# FRCTL_A_367.0 register map
Vendor: Texas Instruments
Peripheral module from a debugger description file (folder msp430).
Registers are 16-bit, read-write, no defined reset value unless marked. A register's access mark holds for its fields unless they carry their own. Offsets are as the file gives them; lines under a group give offsets from that group; [hi:lo] are bit positions; {n}, {i} and the like mark numbered series; 'fields as' and 'values as' point back to an identical list; <NAME> marks a mode.

## FRCTL_A
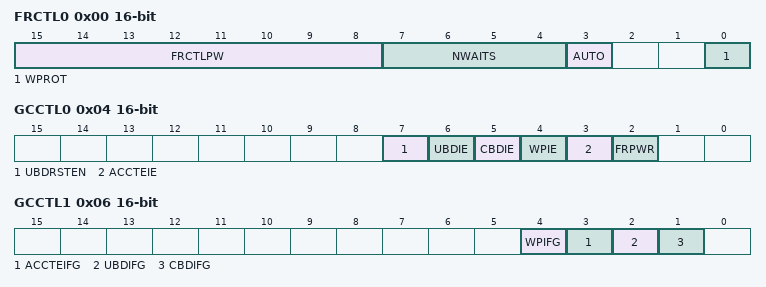
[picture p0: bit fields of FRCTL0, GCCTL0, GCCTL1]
0x00 FRCTL0 — FRAM Controller A Control Register 0
  [15:8] FRCTLPW — FRCTLPW password
  [7:4] NWAITS — Wait state numbers
    {v}=FRAM wait states: {v} (v=0..15)
  [3] AUTO — Enable automatic Wait State Mode
    0=User Wait State Mode. The NWAITS[3:0] is used for the FRAM wait state.; 1=Auto mode. The NWAITS[3:0] is ignored. Wait states are generated automatically by the internal FRAM controller state machine.
  [0] WPROT — Write Protection Enable
    0=Disable Write Protection. Write to FRAM memory is allowed.; 1=Enable Write Protection. Write to FRAM memory is not allowed. In case a write access is attempted, the WPIFG (Write Protection Flag) bit will be set.
0x04 GCCTL0 — General Control Register 0
  [7] UBDRSTEN — Enable Power Up Clear (PUC) reset for the uncorrectable bit error detection flag (UBDIFG)
    0=PUC not initiated on uncorrectable bit error detection flag; 1=PUC initiated on uncorrectable bit error detection flag. Generates vector in SYSRSTIV. Clear the UBDIE bit.
  [6] UBDIE — Enable NMI event for the uncorrectable bit error detection flag (UBDIFG)
    0=Disable NMI for the uncorrectable bit error detection flag (UBDIFG); 1=Enable NMI for the uncorrectable bit error detection flag (UBDIFG). Generates vector in SYSSNIV. Clear the UBDRSTEN bit.
  [5] CBDIE — Enable NMI event for the correctable bit error detection flag (CBDIFG)
    0=Disable NMI for the correctable bit error detection flag (CBDIFG); 1=Disable NMI for the correctable bit error detection flag (CBDIFG). Generates vector in SYSSNIV.
  [4] WPIE — Enable NMI event for the Write Protection Detection flag (WPIFG)
    0=Disable NMI for the Write Protection Detection flag (WPIFG); 1=Enable NMI for the Write Protection Detection flag (WPIFG). Generates vector in SYSSNIV.
  [3] ACCTEIE — Enable NMI event for the Access time error flag (ACCTEIFG)
    0=Disable NMI for the Access time error flag (ACCTEIFG); 1=Enable NMI for the Access time error flag (ACCTEIFG). Generates vector in SYSSNIV.
  [2] FRPWR — FRAM Memory Power Control Request
    0=Enable INACTIVE mode; 1=Enable ACTIVE mode
0x06 GCCTL1 — General Control Register 1
  [4] WPIFG — Write Protection Detection flag
    0=No interrupt pending; 1=Interrupt pending. Can be cleared by writing '0' or by reading SYSSNIV when it is the highest pending interrupt.
  [3] ACCTEIFG — Access time error flag
    values as WPIFG
  [2] UBDIFG — FRAM uncorrectable bit error detection flag
    values as WPIFG
  [1] CBDIFG — FRAM correctable bit error detection flag
    0=No interrupt is pending; 1=Interrupt pending. Can be cleared by writing '0' or by reading SYSSNIV if it is the highest pending interrupt.
